# LPC11Cxx register map
File version: 9
CPU: CM0 r0p0, little endian, no MPU, no FPU, 0x2 interrupt priority bits, 0x0 interrupts
Registers are 32-bit, read-write, reset 0x0 unless marked. A register's access mark holds for its fields unless they carry their own. Offsets are from the block's base; [hi:lo] are bit positions; 'fields as' and 'values as' point back to an identical list.

## C_CAN — C_CAN controller
Base 0x40050000
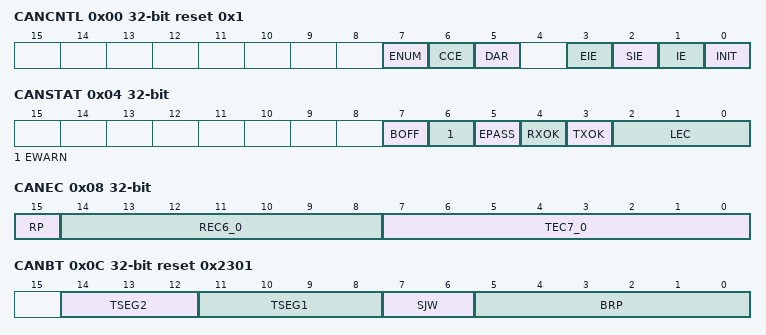
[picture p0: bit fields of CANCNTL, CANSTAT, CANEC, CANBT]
0x00 CANCNTL reset 0x1 — CAN control
  [7] ENUM — Test mode enable
    0=NORMAL_OPERATION; 1=TEST_MODE
  [6] CCE — Configuration change enable
    0=THE_CPU_HAS_NO_WRITE (The CPU has no write access to the bit timing register.); 1=THE_CPU_HAS_WRITE_AC (The CPU has write access to the CANBT register while the INIT bit is one.)
  [5] DAR — Disable automatic retransmission
    0=AUTOMATIC_RETRANSMIS (Automatic retransmission of disturbed messages enabled.); 1=AUTOMATIC_RETRANSMIS (Automatic retransmission disabled.)
  [3] EIE — Error interrupt enable
    0=DISABLE_ERROR_INTERR (Disable error interrupt. No error status interrupt will be generated.); 1=ENABLE_ERROR_INTERRU (Enable error interrupt. A change in the bits BOFF or EWARN in the CANSTAT registers will generate an interrupt.)
  [2] SIE — Status change interrupt enable
    0=DISABLE_STATUS_CHANG (Disable status change interrupts. No status change interrupt will be generated.); 1=ENABLE_STATUS_CHANGE (Enable status change interrupts. A status change interrupt will be generated when a message transfer is successfully completed or a CAN bus error is detected.)
  [1] IE — Module interrupt enable
    0=DISABLE_CAN_INTERRUP (Disable CAN interrupts. The interrupt line is always HIGH.); 1=ENABLE_CAN_INTERRUPT (Enable CAN interrupts. The interrupt line is set to LOW and remains LOW until all pending interrupts are cleared.)
  [0] INIT — Initialization
    0=NORMAL_OPERATION; 1=INITIALIZATION_IS_ST (Initialization is started. On reset, software needs to initialize the CAN controller.)
0x04 CANSTAT — Status register
  [7] BOFF — Busoff status
    0=THE_CAN_MODULE_IS_NO (The CAN module is not in busoff.); 1=THE_CAN_CONTROLLER_I (The CAN controller is in busoff state.)
  [6] EWARN — Warning status
    0=BELOW_LIMIT (Below limit. Both error counters are below the error warning limit of 96.); 1=AT_LIMIT (At limit. At least one of the error counters in the EC has reached the error warning limit of 96.)
  [5] EPASS — Error passive
    0=ACTIVE (Active. The CAN controller is in the error active state.); 1=PASSIVE (Passive. The CAN controller is in the error passive state as defined in the CAN 2.0 specification.)
  [4] RXOK — Received a message successfully This bit must be reset by the CPU. It is never reset by the CAN controller.
    0=NO_RECEIVE (No receive. Since this bit was last reset by the CPU, no message has been successfully received.); 1=SUCCESSFUL_RECEIVE (Successful receive.Since this bit was last set to zero by the CPU, a message has been successfully received independent of the result of acceptance filtering.)
  [3] TXOK — Transmitted a message successfully This bit must be reset by the CPU. It is never reset by the CAN controller.
    0=NO_TRANSMIT (No transmit. Since this bit was last reset by the CPU, no message has been successfully transmitted.); 1=SUCCESSFUL_TRANSMIT (Successful transmit. Since this bit was last reset by the CPU, a message has been successfully transmitted (error free and acknowledged by at least one other node).)
  [2:0] LEC — Last error code Type of the last error to occur on the CAN bus.The LEC field holds a code which indicates the type of the last error to occur on the CAN bus. This field will be cleared to 0 when a message has been transferred (reception or transmission) without error. The unused code 111 may be written by the CPU to check for updates.
    0=NO_ERROR; 1=STUFF_ERROR_MORE_TH (Stuff error: More than 5 equal bits in a sequence have occurred in a part of a received message where this is not allowed.); 2=FORM_ERROR_A_FIXED (Form error: A fixed format part of a received frame has the wrong format.); 3=ACKERROR_THE_MESSAG (AckError: The message this CAN core transmitted was not acknowledged.); 4=BIT1ERROR_DURING_TH (Bit1Error: During the transmission of a message (with the exception of the arbitration field), the device wanted to send a HIGH/recessive level (bit of logical value 1), but the monitored bus value was LOW/dominant.); 5=BIT0ERROR_DURING_TH (Bit0Error: During the transmission of a message (or acknowledge bit, or active error flag, or overload flag), the device wanted to send a LOW/dominant level (data or identifier bit logical value 0), but the monitored Bus value was HIGH/recessive. During busoff recovery this status is set each time a sequence of 11 HIGH/recessive bits has been monitored. This enables the CPU to monitor the proceeding of the busoff recovery sequence (indicating the bus is not stuck at LOW/dominant or continuously disturbed).); 6=CRCERROR_THE_CRC_CH (CRCError: The CRC checksum was incorrect in the message received.); 7=UNUSED_NO_CAN_BUS_E (Unused: No CAN bus event was detected (written by the CPU).)
0x08 CANEC ro — Error counter
  [15] RP — Receive error passive
    0=THE_RECEIVE_COUNTER (The receive counter is below the error passive level.); 1=THE_RECEIVE_COUNTER (The receive counter has reached the error passive level as defined in the CAN2.0 specification.)
  [14:8] REC6_0 — Receive error counter Current value of the receive error counter (maximum value 127).
  [7:0] TEC7_0 — Transmit error counter Current value of the transmit error counter (maximum value 255)
0x0C CANBT reset 0x2301 — Bit timing register
  [14:12] TSEG2 — Time segment after the sample point Valid values are 0 to 7.[1]
  [11:8] TSEG1 — Time segment before the sample point Valid values are 1 to 15.[1]
  [7:6] SJW — (Re)synchronization jump width Valid programmed values are 0 to 3.[1]
  [5:0] BRP — Baud rate prescaler The value by which the oscillator frequency is divided for generating the bit time quanta. The bit time is built up from a multiple of this quanta. Valid values for the Baud Rate Prescaler are 0 to 63.[1]
0x10 CANINT ro — Interrupt register
  [15:0] INTID — 0x0000 = No interrupt is pending. 0x0001 - 0x0020 = Number of message object which caused the interrupt. 0x0021 - 0x7FFF = Unused 0x8000 = Status interrupt 0x8001 - 0xFFFF = Unused
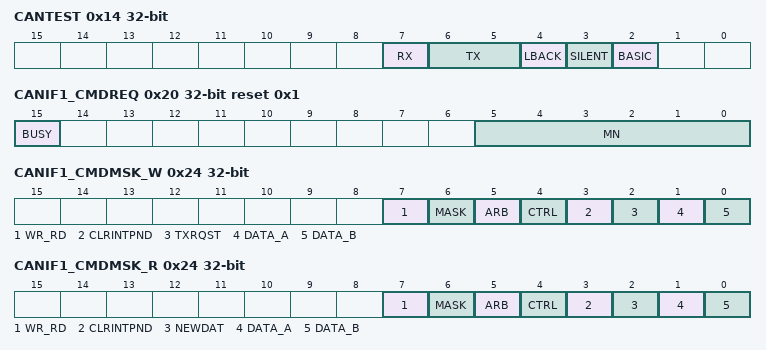
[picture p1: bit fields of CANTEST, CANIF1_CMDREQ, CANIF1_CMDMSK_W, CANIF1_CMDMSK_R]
0x14 CANTEST reset not defined — Test register
  [7] RX — Monitors the actual value of the CAN_RXD pin.
    0=RECESSIVE (Recessive. The CAN bus is recessive (CAN_RXD = 1).); 1=DOMINANT (Dominant. The CAN bus is dominant (CAN_RXD = 0).)
  [6:5] TX — Control of CAN_TXD pins
    0=CONTROLLER (Controller. Level at the CAN_TXD pin is controlled by the CAN controller. This is the value at reset.); 1=SAMPLE_POINT (Sample point. The sample point can be monitored at the CAN_TXD pin.); 2=LOW (Low. CAN_TXD pin is driven LOW/dominant.); 3=HOGH (Hogh. CAN_TXD pin is driven HIGH/recessive.)
  [4] LBACK — Loop back mode
    0=DISABLED (Disabled. Loop back mode is disabled.); 1=ENABLED (Enabled. Loop back mode is enabled.)
  [3] SILENT — Silent mode
    0=NORMAL_OPERATION; 1=SILENT_MODE (Silent mode. The module is in silent mode.)
  [2] BASIC — Basic mode
    0=DISABLED (Disabled. Basic mode disabled.); 1=ENABLED (Enabled. IF1 registers used as TX buffer, IF2 registers used as RX buffer.)
0x18 CANBRPE — Baud rate prescaler extension register
  [3:0] BRPE — Baud rate prescaler extension By programming BRPE the Baud Rate Prescaler can be extended to values up to 1023. Hardware interprets the value as the value of BRPE (MSBs) and BRP (LSBs) plus one. Allowed values are 0 to 15.
0x20 CANIF1_CMDREQ reset 0x1 — Message interface 1 command request
  [15] BUSY — BUSY flag
    0=DONE (Done. Set to zero by hardware when read/write action to this Command request register has finished.); 1=BUSY (Busy. Set to one by hardware when writing to this Command request register.)
  [5:0] MN — Message number 0x01 - 0x20 = Valid message numbers. The message object in the message RAM is selected for data transfer. 0x00 = Not a valid message number. This value is interpreted as 0x20.[1] 0x21 - 0x3F = Not a valid message number. This value is interpreted as 0x01 - 0x1F.[1]
0x24 CANIF1_CMDMSK_W — Message interface 1 command mask (write direction)
  [7] WR_RD — Write transfer Transfer data from the selected message buffer registers to the message object addressed by the command request register CANIFn_CMDREQ.
  [6] MASK — Access mask bits
    0=UNCHANGED (Unchanged. Mask bits unchanged.); 1=TRANSFER (Transfer. Transfer Identifier MASK + MDIR + MXTD to message object.)
  [5] ARB — Access arbitration bits
    0=UNCHANGED (Unchanged. Arbitration bits unchanged.); 1=TRANSFER (Transfer. Transfer Identifier, DIR, XTD, and MSGVAL bits to message object.)
  [4] CTRL — Access control bits
    0=UNCHANGED (Unchanged. Control bits unchanged.); 1=TRANSFER (Transfer. Transfer control bits to message object)
  [3] CLRINTPND — This bit is ignored in the write direction.
  [2] TXRQST — Access transmission request bit
    0=NO_TRANSMISSION_REQU (No transmission request. TXRQSRT bit unchanged in IF1/2_MCTRL. If a transmission is requested by programming this bit, the TXRQST bit in the CANIFn_MCTRL register is ignored.); 1=REQUEST_A_TRANSMISSI (Request a transmission. Set the TXRQST bit IF1/2_MCTRL.)
  [1] DATA_A — Access data bytes 0-3
    0=UNCHANGED (Unchanged. Data bytes 0-3 unchanged.); 1=TRANSFER (Transfer. Transfer data bytes 0-3 to message object.)
  [0] DATA_B — Access data bytes 4-7
    0=UNCHANGED (Unchanged. Data bytes 4-7 unchanged.); 1=TRANSFER (Transfer. Transfer data bytes 4-7 to message object.)
0x24 CANIF1_CMDMSK_R — Message interface 1 command mask (read direction)
  [7] WR_RD — Read transfer Transfer data from the message object addressed by the command request register to the selected message buffer registers CANIFn_CMDREQ.
  [6] MASK — Access mask bits
    0=UNCHANGED (Unchanged. Mask bits unchanged.); 1=TRANSFER (Transfer. Transfer Identifier MASK + MDIR + MXTD to IFx message buffer register.)
  [5] ARB — Access arbitration bits
    0=UNCHANGED (Unchanged. Arbitration bits unchanged.); 1=TRANSFER (Transfer. Transfer Identifier, DIR, XTD, and MSGVAL bits to IFx message buffer register.)
  [4] CTRL — Access control bits
    0=UNCHANGED (Unchanged. Control bits unchanged.); 1=TRANSFER (Transfer. Transfer control bits to IFx message buffer.)
  [3] CLRINTPND — Clear interrupt pending bit.
    0=UNCHANGED (Unchanged. INTPND bit remains unchanged.); 1=CLEAR (Clear. Clear INTPND bit in the message object.)
  [2] NEWDAT — Access new data bit
    0=UNCHANGED (Unchanged. NEWDAT bit remains unchanged. A read access to a message object can be combined with the reset of the control bits INTPND and NEWDAT in IF1/2_MCTRL. The values of these bits transferred to the IFx Message Control Register always reflect the status before resetting these bits.); 1=CLEAR (Clear. Clear NEWDAT bit in the message object.)
  [1] DATA_A — Access data bytes 0-3
    0=UNCHANGED (Unchanged. Data bytes 0-3 unchanged.); 1=TRANSFER (Transfer. Transfer data bytes 0-3 to IFx message buffer.)
  [0] DATA_B — Access data bytes 4-7
    0=UNCHANGED (Unchanged. Data bytes 4-7 unchanged.); 1=TRANSFER (Transfer. Transfer data bytes 4-7 to IFx message buffer register.)
0x28 CANIF1_MSK1 reset 0xFFFF — Message interface 1 mask 1
  [15:0] MSK15_0 — Identifier mask [15:0]
    0=MATCH (Match. The corresponding bit in the identifier of the message cannot inhibit the match in the acceptance filtering.); 1=MASK (Mask. The corresponding identifier bit is used for acceptance filtering.)
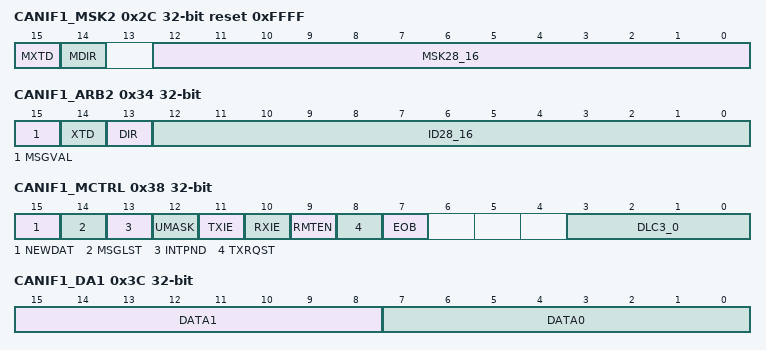
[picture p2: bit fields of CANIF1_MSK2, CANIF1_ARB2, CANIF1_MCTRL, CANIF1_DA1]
0x2C CANIF1_MSK2 reset 0xFFFF — Message interface 1 mask 2
  [15] MXTD — Mask extend identifier
    0=WITHOUT_XTD (Without XTD. The extended identifier bit (XTD) has no effect on acceptance filtering.); 1=WITH_XTD (With XTD. The extended identifier bit (XTD) is used for acceptance filtering.)
  [14] MDIR — Mask message direction
    0=WITHOUT_DIR_BIT (Without DIR bit. The message direction bit (DIR) has no effect on acceptance filtering.); 1=WITH_DIR_BIT (With DIR bit. The message direction bit (DIR) is used for acceptance filtering.)
  [12:0] MSK28_16 — Identifier mask [28:16]
    values as CANIF1_MSK1.MSK15_0
0x30 CANIF1_ARB1 — Message interface 1 arbitration 1
  [15:0] ID15_0 — Message identifier [15:0] 29-bit identifier (extended frame) 11-bit identifier (standard frame)
0x34 CANIF1_ARB2 — Message interface 1 arbitration 2
  [15] MSGVAL — Message valid The CPU must reset the MSGVAL bit of all unused Messages Objects during the initialization before it resets bit INIT in the CAN Control Register. This bit must also be reset before the identifier ID28:0, the control bits XTD, DIR, or the Data Length Code DLC3:0 are modified, or if the Messages Object is no longer required.
    0=INVALID (Invalid. The message object is ignored by the message handler.); 1=VALID (Valid. The message object is configured and should be considered by the message handler.)
  [14] XTD — Extend identifier
    0=STANDARD (Standard. The 11-bit standard identifier will be used for this message object.); 1=EXTENDED (Extended. The 29-bit extended identifier will be used for this message object.)
  [13] DIR — Message direction
    0=RECEIVE (Receive. On TXRQST, a Remote Frame with the identifier of this Message Object is transmitted. On reception of a Data Frame with matching identifier, that message is stored in this Message Object.); 1=TANSMIT (Tansmit. On TXRQST, the respective Message Object is transmitted as a Data Frame. On reception of a Remote Frame with matching identifier, the TXRQST bit of this Message Object is set (if RMTEN = one).)
  [12:0] ID28_16 — Message identifier 29-bit identifier (extended frame) 11-bit identifier (standard frame)
0x38 CANIF1_MCTRL — Message interface 1 message control
  [15] NEWDAT — New data
    0=NO_NEW_DATA (No new data. No new data has been written into the data portion of this message object by the message handler since this flag was cleared last by the CPU.); 1=NEW_DATA (New data. The message handler or the CPU has written new data into the data portion of this message object.)
  [14] MSGLST — Message lost (only valid for message objects in the direction receive).
    0=NOT_LOST (Not lost. No message lost since this bit was reset last by the CPU.); 1=LOST (Lost. The Message Handler stored a new message into this object when NEWDAT was still set, the CPU has lost a message.)
  [13] INTPND — Interrupt pending
    0=NOT_PENDING (Not pending. This message object is not the source of an interrupt.); 1=PENDING (Pending. This message object is the source of an interrupt. The Interrupt Identifier in the Interrupt Register will point to this message object if there is no other interrupt source with higher priority.)
  [12] UMASK — Use acceptance mask If UMASK is set to 1, the message object's mask bits have to be programmed during initialization of the message object before MAGVAL is set to 1.
    0=IGNORE (Ignore. Mask ignored.); 1=USE (Use. Use mask (MSK[28:0], MXTD, and MDIR) for acceptance filtering.)
  [11] TXIE — Transmit interrupt enable
    0=INTPND_UNCHANGED (INTPND unchanged. The INTPND bit will be left unchanged after a successful transmission of a frame.); 1=INTPND_SET (INTPND set. INTPND will be set after a successful transmission of a frame.)
  [10] RXIE — Receive interrupt enable
    0=INTPND_UNCHANGED (INTPND unchanged. INTPND will be left unchanged after successful reception of a frame.); 1=INTPND_SET (INTPND set. INTPND will be set after successful reception of a frame.)
  [9] RMTEN — Remote enable
    0=TXRQST_UNCHANGED (TXRQST unchanged. At the reception of a remote frame, TXRQST is left unchanged.); 1=TXRQST_SET (TXRQST set. At the reception of a remote frame, TXRQST is set.)
  [8] TXRQST — Transmit request
    0=NOT_WAITING (Not waiting. This message object is not waiting for transmission.); 1=WAITING (Waiting. The transmission of this message object is requested and is not yet done)
  [7] EOB — End of buffer
    0=NOT_END_OF_BUFFER (Not end of buffer. Message object belongs to a FIFO buffer and is not the last message object of that FIFO buffer.); 1=END_OF_BUFFER (End of buffer. Single message object or last message object of a FIFO buffer.)
  [3:0] DLC3_0 — Data length code 3:0 The Data Length Code of a Message Object must be defined the same as in all the corresponding objects with the same identifier at other nodes. When the Message Handler stores a data frame, it will write the DLC to the value given by the received message. 0000 - 1000 = Data frame has 0 - 8 data bytes. 1001 - 1111 = Data frame has 8 data bytes.
0x3C CANIF1_DA1 — Message interface 1 data A1
  [15:8] DATA1 — Data byte 1
  [7:0] DATA0 — Data byte 0
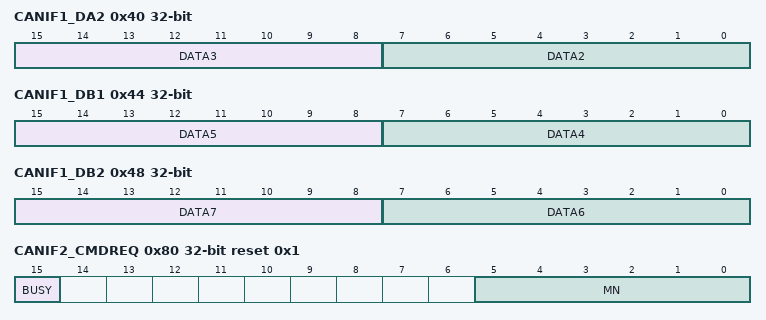
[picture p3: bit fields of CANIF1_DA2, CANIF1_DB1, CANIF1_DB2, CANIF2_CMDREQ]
0x40 CANIF1_DA2 — Message interface 1 data A2
  [15:8] DATA3 — Data byte 3
  [7:0] DATA2 — Data byte 2
0x44 CANIF1_DB1 — Message interface 1 data B1
  [15:8] DATA5 — Data byte 5
  [7:0] DATA4 — Data byte 4
0x48 CANIF1_DB2 — Message interface 1 data B2
  [15:8] DATA7 — Data byte 7
  [7:0] DATA6 — Data byte 6
0x80 CANIF2_CMDREQ reset 0x1 — Message interface 1 command request
  fields as CANIF1_CMDREQ
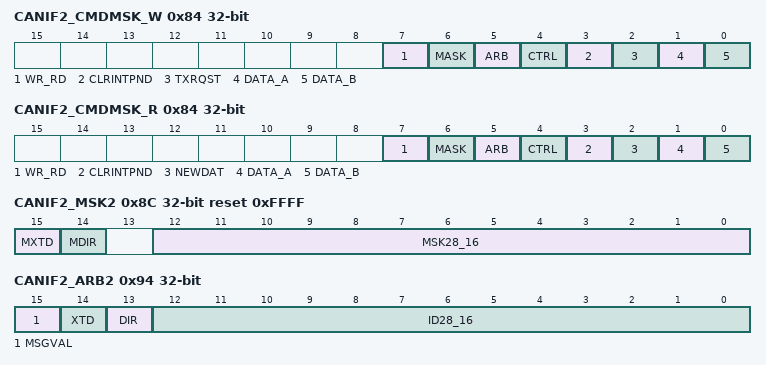
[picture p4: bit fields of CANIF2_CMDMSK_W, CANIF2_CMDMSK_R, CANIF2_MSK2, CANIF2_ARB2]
0x84 CANIF2_CMDMSK_W — Message interface 1 command mask (write direction)
  fields as CANIF1_CMDMSK_W
0x84 CANIF2_CMDMSK_R — Message interface 1 command mask (read direction)
  fields as CANIF1_CMDMSK_R
0x88 CANIF2_MSK1 reset 0xFFFF — Message interface 1 mask 1
  fields as CANIF1_MSK1
0x8C CANIF2_MSK2 reset 0xFFFF — Message interface 1 mask 2
  fields as CANIF1_MSK2
0x90 CANIF2_ARB1 — Message interface 1 arbitration 1
  fields as CANIF1_ARB1
0x94 CANIF2_ARB2 — Message interface 1 arbitration 2
  fields as CANIF1_ARB2
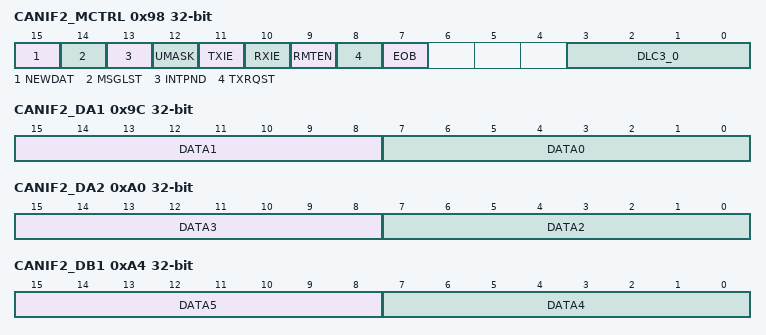
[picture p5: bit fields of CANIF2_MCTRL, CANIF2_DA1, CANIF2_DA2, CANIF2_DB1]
0x98 CANIF2_MCTRL — Message interface 1 message control
  fields as CANIF1_MCTRL
0x9C CANIF2_DA1 — Message interface 1 data A1
  [15:8] DATA1 — Data byte 1
  [7:0] DATA0 — Data byte 0
0xA0 CANIF2_DA2 — Message interface 1 data A2
  [15:8] DATA3 — Data byte 3
  [7:0] DATA2 — Data byte 2
0xA4 CANIF2_DB1 — Message interface 1 data B1
  [15:8] DATA5 — Data byte 5
  [7:0] DATA4 — Data byte 4
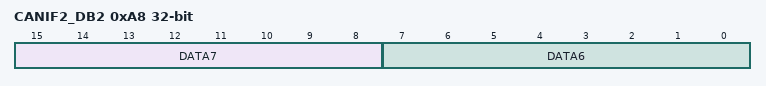
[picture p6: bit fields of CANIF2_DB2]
0xA8 CANIF2_DB2 — Message interface 1 data B2
  [15:8] DATA7 — Data byte 7
  [7:0] DATA6 — Data byte 6
0x100 CANTXREQ1 ro — Transmission request 1
  [15:0] TXRQST16_1 — Transmission request bit of message objects 16 to 1. 0 = This message object is not waiting for transmission. 1 = The transmission of this message object is requested and not yet done.
0x104 CANTXREQ2 ro — Transmission request 2
  [15:0] TXRQST32_17 — Transmission request bit of message objects 32 to 17. 0 = This message object is not waiting for transmission. 1 = The transmission of this message object is requested and not yet done.
0x120 CANND1 ro — New data 1
  [15:0] NEWDAT16_1 — New data bits of message objects 16 to 1. 0 = No new data has been written into the data portion of this Message Object by the Message Handler since last time this flag was cleared by the CPU. 1 = The Message Handler or the CPU has written new data into the data portion of this Message Object.
0x124 CANND2 ro — New data 2
  [15:0] NEWDAT32_17 — New data bits of message objects 32 to 17. 0 = No new data has been written into the data portion of this Message Object by the Message Handler since last time this flag was cleared by the CPU. 1 = The Message Handler or the CPU has written new data into the data portion of this Message Object.
0x140 CANIR1 ro — Interrupt pending 1
  [15:0] INTPND16_1 — Interrupt pending bits of message objects 16 to 1. 0 = This message object is ignored by the message handler. 1 = This message object is the source of an interrupt.
0x144 CANIR2 ro — Interrupt pending 2
  [15:0] INTPND32_17 — Interrupt pending bits of message objects 32 to 17. 0 = This message object is ignored by the message handler. 1 = This message object is the source of an interrupt.
0x160 CANMSGV1 ro — Message valid 1
  [15:0] MSGVAL16_1 — Message valid bits of message objects 16 to 1. 0 = This message object is ignored by the message handler. 1 = This message object is configured and should be considered by the message handler.
0x164 CANMSGV2 ro — Message valid 2
  [15:0] MSGVAL32_17 — Message valid bits of message objects 32 to 17. 0 = This message object is ignored by the message handler. 1 = This message object is configured and should be considered by the message handler.
0x180 CANCLKDIV — Can clock divider register
  [3:0] CLKDIVVAL — Clock divider value. CAN_CLK = PCLK/(CLKDIVVAL +1) 0000: CAN_CLK = PCLK divided by 1. 0001: CAN_CLK = PCLK divided by 2. 0010: CAN_CLK = PCLK divided by 3 0011: CAN_CLK = PCLK divided by 4. ... 1111: CAN_CLK = PCLK divided by 16.
